AUTOSAR XML (schema 4-0-3)
package /ComponentTypes
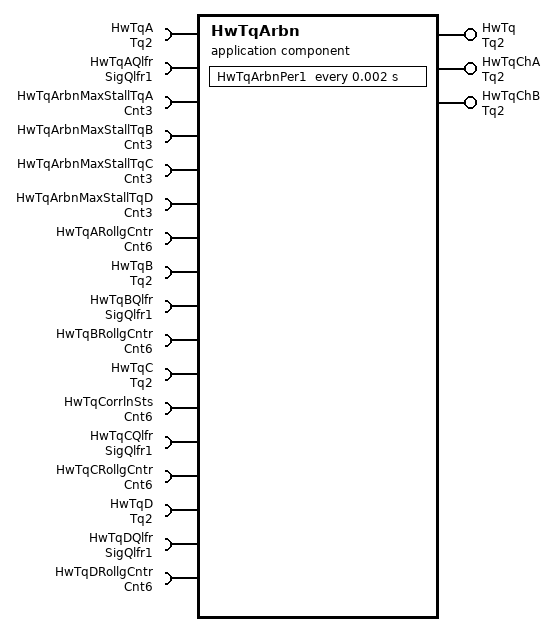
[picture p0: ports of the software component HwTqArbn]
  application sw component type HwTqArbn
    provide port HwTq: nonqueued-sender-com-spec{data-element=Val, init-value=0}, provided-interface=Tq2
    provide port HwTqChA: nonqueued-sender-com-spec{data-element=Val, init-value=0}, provided-interface=Tq2
    provide port HwTqChB: nonqueued-sender-com-spec{data-element=Val, init-value=0}, provided-interface=Tq2
    17 x require port:
      HwTqA: nonqueued-receiver-com-spec{data-element=Val, filter=data-filter-type=ALWAYS, init-value=0}, required-interface=Tq2
      HwTqAQlfr: nonqueued-receiver-com-spec{data-element=Val, filter=data-filter-type=ALWAYS, init-value=0}, required-interface=SigQlfr1
      HwTqArbnMaxStallTqA: parameter-require-com-spec{init-value=10, parameter=Val}, required-interface=Cnt3
      HwTqArbnMaxStallTqB: parameter-require-com-spec{init-value=10, parameter=Val}, required-interface=Cnt3
      HwTqArbnMaxStallTqC: parameter-require-com-spec{init-value=10, parameter=Val}, required-interface=Cnt3
      HwTqArbnMaxStallTqD: parameter-require-com-spec{init-value=10, parameter=Val}, required-interface=Cnt3
      HwTqARollgCntr: nonqueued-receiver-com-spec{data-element=Val, filter=data-filter-type=ALWAYS, init-value=0}, required-interface=Cnt6
      HwTqB: nonqueued-receiver-com-spec{data-element=Val, filter=data-filter-type=ALWAYS, init-value=0}, required-interface=Tq2
      HwTqBQlfr: nonqueued-receiver-com-spec{data-element=Val, filter=data-filter-type=ALWAYS, init-value=0}, required-interface=SigQlfr1
      HwTqBRollgCntr: nonqueued-receiver-com-spec{data-element=Val, filter=data-filter-type=ALWAYS, init-value=0}, required-interface=Cnt6
      HwTqC: nonqueued-receiver-com-spec{data-element=Val, filter=data-filter-type=ALWAYS, init-value=0}, required-interface=Tq2
      HwTqCorrlnSts: nonqueued-receiver-com-spec{data-element=Val, filter=data-filter-type=ALWAYS, init-value=15}, required-interface=Cnt6
      HwTqCQlfr: nonqueued-receiver-com-spec{data-element=Val, filter=data-filter-type=ALWAYS, init-value=0}, required-interface=SigQlfr1
      HwTqCRollgCntr: nonqueued-receiver-com-spec{data-element=Val, filter=data-filter-type=ALWAYS, init-value=0}, required-interface=Cnt6
      HwTqD: nonqueued-receiver-com-spec{data-element=Val, filter=data-filter-type=ALWAYS, init-value=0}, required-interface=Tq2
      HwTqDQlfr: nonqueued-receiver-com-spec{data-element=Val, filter=data-filter-type=ALWAYS, init-value=0}, required-interface=SigQlfr1
      HwTqDRollgCntr: nonqueued-receiver-com-spec{data-element=Val, filter=data-filter-type=ALWAYS, init-value=0}, required-interface=Cnt6
    behavior HwTqArbn_InternalBehavior: data-type-mapping=Nexteer
      ar-typed-per-instance-memorys:
        10 x data, all with sw-calibration-access=READ-ONLY:
          dHwTqArbnChAAvl: type=boolean
          dHwTqArbnChBAvl: type=boolean
          HwTqArbnTqARollgCntrPrev: type=uint8
          HwTqArbnTqAStallCntrPrev: type=uint8
          HwTqArbnTqBRollgCntrPrev: type=uint8
          HwTqArbnTqBStallCntrPrev: type=uint8
          HwTqArbnTqCRollgCntrPrev: type=uint8
          HwTqArbnTqCStallCntrPrev: type=uint8
          HwTqArbnTqDRollgCntrPrev: type=uint8
          HwTqArbnTqDStallCntrPrev: type=uint8
      timing event TMT_HwTqArbnPer1: start-on-event=HwTqArbnPer1, period=0.002
      runnable HwTqArbnPer1
        data-receive-point-by-arguments:
          13 x access:
            REC_HwTqA_Val: accessed-variable=HwTqA.Val
            REC_HwTqAQlfr_Val: accessed-variable=HwTqAQlfr.Val
            REC_HwTqARollgCntr_Val: accessed-variable=HwTqARollgCntr.Val
            REC_HwTqB_Val: accessed-variable=HwTqB.Val
            REC_HwTqBQlfr_Val: accessed-variable=HwTqBQlfr.Val
            REC_HwTqBRollgCntr_Val: accessed-variable=HwTqBRollgCntr.Val
            REC_HwTqC_Val: accessed-variable=HwTqC.Val
            REC_HwTqCorrlnSts_Val: accessed-variable=HwTqCorrlnSts.Val
            REC_HwTqCQlfr_Val: accessed-variable=HwTqCQlfr.Val
            REC_HwTqCRollgCntr_Val: accessed-variable=HwTqCRollgCntr.Val
            REC_HwTqD_Val: accessed-variable=HwTqD.Val
            REC_HwTqDQlfr_Val: accessed-variable=HwTqDQlfr.Val
            REC_HwTqDRollgCntr_Val: accessed-variable=HwTqDRollgCntr.Val
        data-send-points:
          access SEND_HwTq_Val: accessed-variable=HwTq.Val
          access SEND_HwTqChA_Val: accessed-variable=HwTqChA.Val
          access SEND_HwTqChB_Val: accessed-variable=HwTqChB.Val
  swc implementation HwTqArbn_Implementation: behavior=HwTqArbn_InternalBehavior
    code-descriptors:
      code Default: artifact-descriptors=autosar-engineering-object={short-label=Default, category=SWSRC}
